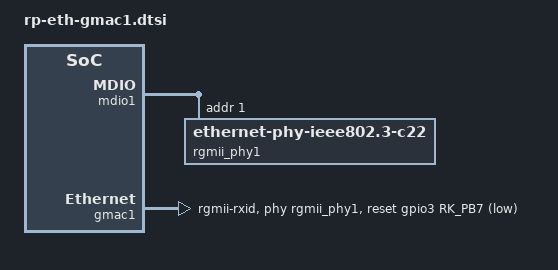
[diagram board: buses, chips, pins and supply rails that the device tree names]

&mdio1 {
    rgmii_phy1: phy@1 {
        compatible = "ethernet-phy-ieee802.3-c22";
        reg = <0x1>;
        clocks = <&cru REFCLKO25M_ETH1_OUT>;
    };
};

&gmac1 {
    // Use rgmii-rxid mode to disable rx delay inside Soc
    phy-mode = "rgmii-rxid";
    clock_in_out = "input";

    snps,reset-gpio = <&gpio3 RK_PB7 GPIO_ACTIVE_LOW>;
    snps,reset-active-low;
    // Reset time is 20ms, 100ms for rtl8211f 
    snps,reset-delays-us = <0 20000 100000>;

    pinctrl-names = "default";
    pinctrl-0 = <&gmac1_miim
             &gmac1_tx_bus2
             &gmac1_rx_bus2
             &gmac1_rgmii_clk
             &gmac1_rgmii_bus
            &gmac1_clkinout
            &eth1_pins>;

    tx_delay = <0x44>;
    // rx_delay = <0x4f>;

    phy-handle = <&rgmii_phy1>;
    status = "okay";
};
